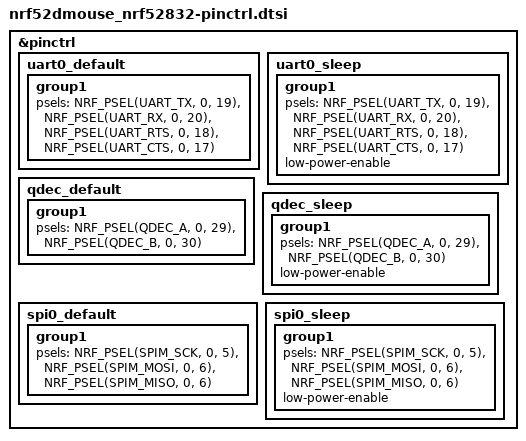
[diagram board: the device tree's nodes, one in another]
/*
 * Copyright (c) 2022 Nordic Semiconductor ASA
 *
 * SPDX-License-Identifier: LicenseRef-Nordic-5-Clause
 */
&pinctrl {
	uart0_default: uart0_default {
		group1 {
			psels = <NRF_PSEL(UART_TX, 0, 19)>,
				<NRF_PSEL(UART_RX, 0, 20)>,
				<NRF_PSEL(UART_RTS, 0, 18)>,
				<NRF_PSEL(UART_CTS, 0, 17)>;
		};
	};

	uart0_sleep: uart0_sleep {
		group1 {
			psels = <NRF_PSEL(UART_TX, 0, 19)>,
				<NRF_PSEL(UART_RX, 0, 20)>,
				<NRF_PSEL(UART_RTS, 0, 18)>,
				<NRF_PSEL(UART_CTS, 0, 17)>;
			low-power-enable;
		};
	};

	qdec_default: qdec_default {
		group1 {
			psels = <NRF_PSEL(QDEC_A, 0, 29)>,
				<NRF_PSEL(QDEC_B, 0, 30)>;
		};
	};

	qdec_sleep: qdec_sleep {
		group1 {
			psels = <NRF_PSEL(QDEC_A, 0, 29)>,
				<NRF_PSEL(QDEC_B, 0, 30)>;
			low-power-enable;
		};
	};

	spi0_default: spi0_default {
		group1 {
			psels = <NRF_PSEL(SPIM_SCK, 0, 5)>,
				<NRF_PSEL(SPIM_MOSI, 0, 6)>,
				<NRF_PSEL(SPIM_MISO, 0, 6)>;
		};
	};

	spi0_sleep: spi0_sleep {
		group1 {
			psels = <NRF_PSEL(SPIM_SCK, 0, 5)>,
				<NRF_PSEL(SPIM_MOSI, 0, 6)>,
				<NRF_PSEL(SPIM_MISO, 0, 6)>;
			low-power-enable;
		};
	};

};
